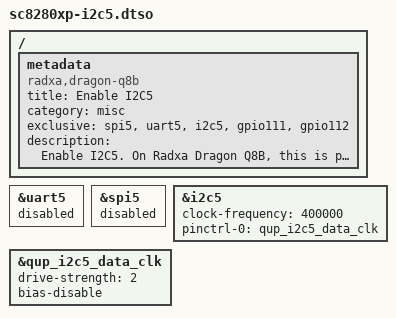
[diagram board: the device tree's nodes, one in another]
// SPDX-License-Identifier: BSD-3-Clause
/*
 * Copyright (c) 2026 Radxa Computer (Shenzhen) Co., Ltd.
 */

/dts-v1/;
/plugin/;

/ {
	metadata {
		title = "Enable I2C5";
		compatible = "radxa,dragon-q8b";
		category = "misc";
		exclusive = "spi5", "uart5", "i2c5", "gpio111", "gpio112";
		description = "Enable I2C5.
On Radxa Dragon Q8B, this is pin 36(scl), 11(sda).";
	};
};

&uart5 {
	status = "disabled";
};

&spi5 {
	status = "disabled";
};

&i2c5 {
	clock-frequency = <400000>;

	pinctrl-0 = <&qup_i2c5_data_clk>;
	pinctrl-names = "default";

	status = "okay";
};

&qup_i2c5_data_clk {
	drive-strength = <2>;
	bias-disable;
};
